# GD32F1x0 register map
File version: 1.0
CPU: CM3 r2p1, little endian, no MPU, no FPU, 4 interrupt priority bits
Registers are 32-bit, read-write, reset 0x0 unless marked. A register's access mark holds for its fields unless they carry their own. Offsets are from the block's base; [hi:lo] are bit positions; {n}, {i} and the like mark numbered series.

## RTC — Real-time clock
Base 0x40002800
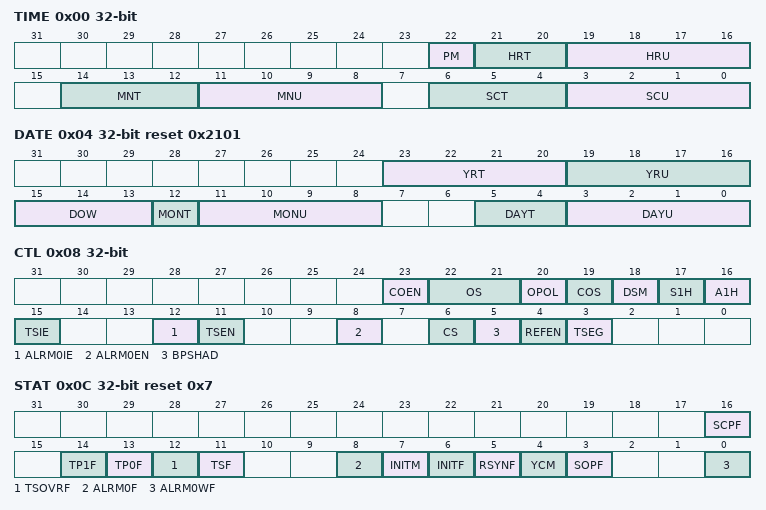
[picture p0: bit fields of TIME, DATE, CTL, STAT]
0x00 TIME — Time of day register
  [22] PM — AM/PM mark
  [21:20] HRT — Hour tens in BCD format
  [19:16] HRU — Hour units in BCD format
  [14:12] MNT — Minute tens in BCD format
  [11:8] MNU — Minute units in BCD format
  [6:4] SCT — Second tens in BCD format
  [3:0] SCU — Second units in BCD format
0x04 DATE reset 0x2101
  [23:20] YRT — Year tens in BCD format
  [19:16] YRU — Year units in BCD format
  [15:13] DOW — Week day units
  [12] MONT — Month tens in BCD format
  [11:8] MONU — Month units in BCD format
  [5:4] DAYT — Date tens in BCD format
  [3:0] DAYU — Date units in BCD format
0x08 CTL access per field — control register
  [23] COEN rw — Calibration output enable
  [22:21] OS rw — Output selection
  [20] OPOL rw — Output polarity
  [19] COS rw — Calibration output selection
  [18] DSM rw — Daylight saving mark
  [17] S1H wo — Subtract 1 hour(winter time change)
  [16] A1H wo — Add 1 hour(summer time change
  [15] TSIE rw — Time-stamp interrupt enable
  [12] ALRM0IE rw — RTC alarm-0 interrupt enable
  [11] TSEN rw — time-stamp function enable
  [8] ALRM0EN rw — Alarm-0 function enable
  [6] CS rw — Clock System
  [5] BPSHAD rw — Shadow registers bypass control
  [4] REFEN rw — Reference clock detection function enable
  [3] TSEG rw — Valid event edge of time-stamp
0x0C STAT access per field reset 0x7 — Status register
  [16] SCPF ro — Smooth calibration pending flag
  [14] TP1F rw — RTC_TAMP1 detected flag
  [13] TP0F rw — RTC_TAMP0 detected flag
  [12] TSOVRF rw — Time-stamp overflow flag
  [11] TSF rw — Time-stamp flag
  [8] ALRM0F rw — Alarm-0 occurs flag
  [7] INITM rw — enter initialization mode
  [6] INITF ro — Initialization state flag
  [5] RSYNF rw — Register synchronization flag
  [4] YCM ro — Year configuration mark
  [3] SOPF ro — Shift function operation pending flag
  [0] ALRM0WF ro — Alarm 0 configuration can be write flag
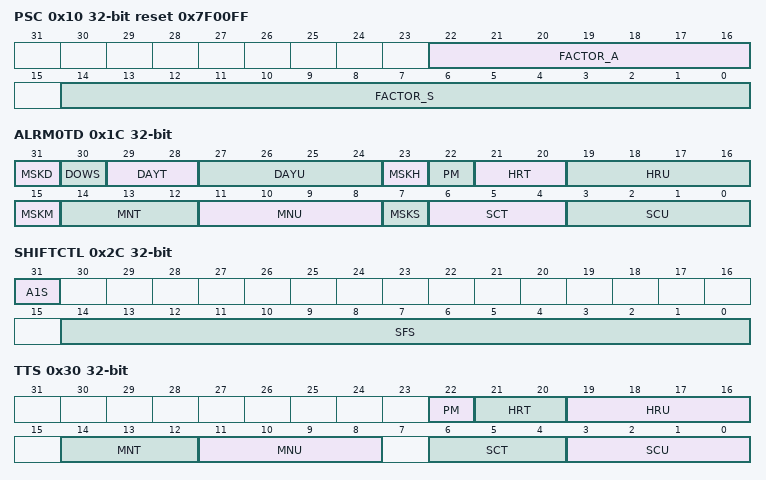
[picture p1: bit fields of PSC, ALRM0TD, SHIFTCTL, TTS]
0x10 PSC reset 0x7F00FF — Time prescaler register
  [22:16] FACTOR_A — Asynchronous prescaler factor
  [14:0] FACTOR_S — Synchronous prescaler factor
0x1C ALRM0TD — Alarm 0 Time and date register
  [31] MSKD — Alarm date mask bit
  [30] DOWS — Day of the week selected
  [29:28] DAYT — Date tens in BCD code
  [27:24] DAYU — Date units or week day in BCD code
  [23] MSKH — Alarm hour mask bit
  [22] PM — AM/PM flag
  [21:20] HRT — Hour tens in BCD code
  [19:16] HRU — Hour units in BCD code
  [15] MSKM — Alarm minutes mask bit
  [14:12] MNT — Minutes tens in BCD code
  [11:8] MNU — Minutes units in BCD code
  [7] MSKS — Alarm second mask bit
  [6:4] SCT — Second tens in BCD code
  [3:0] SCU — Second units in BCD code
0x24 WPK wo — Write protection key register
  [7:0] WPK — Write protection key
0x28 SS ro — sub second register
  [15:0] SSC — Sub second value
0x2C SHIFTCTL wo — Shift function control register
  [31] A1S — One second add
  [14:0] SFS — Subtract a fraction of a second
0x30 TTS ro — Time of time stamp register
  [22] PM — AM/PM mark
  [21:20] HRT — Hour tens in BCD code
  [19:16] HRU — Hour units in BCD code
  [14:12] MNT — Minute tens in BCD code
  [11:8] MNU — Minute units in BCD code
  [6:4] SCT — Second tens in BCD code
  [3:0] SCU — Second units in BCD code
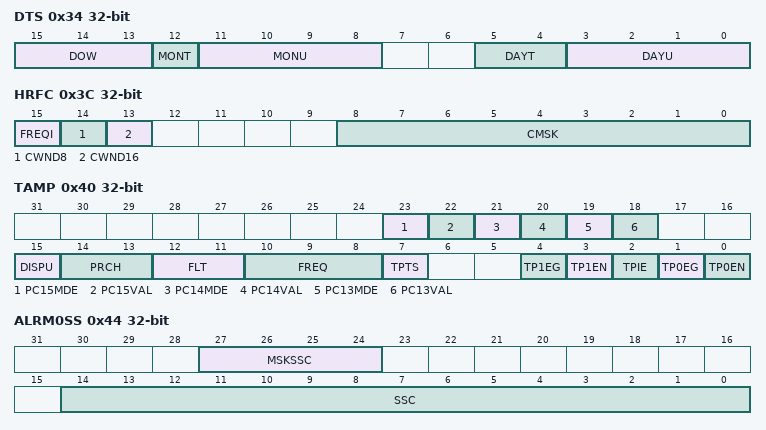
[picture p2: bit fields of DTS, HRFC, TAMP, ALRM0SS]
0x34 DTS ro — Date of time stamp register
  [15:13] DOW — Week day units
  [12] MONT — Month tens in BCD code
  [11:8] MONU — Month units in BCD code
  [5:4] DAYT — Date tens in BCD code
  [3:0] DAYU — Date units in BCD code
0x38 SSTS ro — Sub second of time stamp register
  [15:0] SSC — Sub second value
0x3C HRFC — High resolution frequency compensation register
  [15] FREQI — Increase RTC frequency by 488.5ppm
  [14] CWND8 — Frequency compensation window 8 second selected
  [13] CWND16 — Frequency compensation window 16 second selected
  [8:0] CMSK — Calibration mask number
0x40 TAMP — Tamper register
  [23] PC15MDE — PC15 mode
  [22] PC15VAL — PC15 value
  [21] PC14MDE — PC14 mode
  [20] PC14VAL — PC14 value
  [19] PC13MDE — PC13 mode
  [18] PC13VAL — Alarm output type control/PC13 output value
  [15] DISPU — RTC_TAMPx pull up disable bit
  [14:13] PRCH — Precharge duration time of RTC_TAMPx
  [12:11] FLT — RTC_TAMPx filter count setting
  [10:8] FREQ — Sample frequency of tamper event detection
  [7] TPTS — Make tamper function used for timestamp function
  [4] TP1EG — Tamper 1 event trigger edge for RTC_TAMP1 input
  [3] TP1EN — Tamper 1 detection enable
  [2] TPIE — Tamper detection interrupt enable
  [1] TP0EG — Tamper 0 event trigger edge for RTC_TAMP0 input
  [0] TP0EN — RTC_TAMP1 input detection enable
0x44 ALRM0SS — Alarm 0 sub second register
  [27:24] MSKSSC — Mask control bit of SSC
  [14:0] SSC — Alarm sub second value
{0x50+4i} BKP{i} (i=0..4) — backup register
  [31:0] DATA — Backup domain registers
